AUTOSAR XML (schema 4-2-2)
package /ComponentTypes
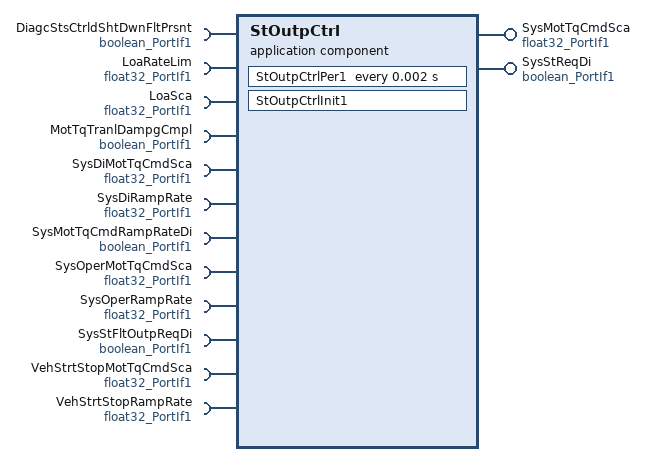
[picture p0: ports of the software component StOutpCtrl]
  application sw component type StOutpCtrl
    provide port SysMotTqCmdSca: nonqueued-sender-com-spec{data-element=Val, init-value=1}, provided-interface=float32_PortIf1
    provide port SysStReqDi: nonqueued-sender-com-spec{data-element=Logl, init-value=0}, provided-interface=boolean_PortIf1
    12 x require port:
      DiagcStsCtrldShtDwnFltPrsnt: nonqueued-receiver-com-spec{data-element=Logl, filter=data-filter-type=ALWAYS, init-value=0}, required-interface=boolean_PortIf1
      LoaRateLim: nonqueued-receiver-com-spec{data-element=Val, filter=data-filter-type=ALWAYS, init-value=1}, required-interface=float32_PortIf1
      LoaSca: nonqueued-receiver-com-spec{data-element=Val, filter=data-filter-type=ALWAYS, init-value=1}, required-interface=float32_PortIf1
      MotTqTranlDampgCmpl: nonqueued-receiver-com-spec{data-element=Logl, filter=data-filter-type=ALWAYS, init-value=0}, required-interface=boolean_PortIf1
      SysDiMotTqCmdSca: nonqueued-receiver-com-spec{data-element=Val, filter=data-filter-type=ALWAYS, init-value=1}, required-interface=float32_PortIf1
      SysDiRampRate: nonqueued-receiver-com-spec{data-element=Val, filter=data-filter-type=ALWAYS, init-value=1}, required-interface=float32_PortIf1
      SysMotTqCmdRampRateDi: nonqueued-receiver-com-spec{data-element=Logl, filter=data-filter-type=ALWAYS, init-value=0}, required-interface=boolean_PortIf1
      SysOperMotTqCmdSca: nonqueued-receiver-com-spec{data-element=Val, filter=data-filter-type=ALWAYS, init-value=1}, required-interface=float32_PortIf1
      SysOperRampRate: nonqueued-receiver-com-spec{data-element=Val, filter=data-filter-type=ALWAYS, init-value=1}, required-interface=float32_PortIf1
      SysStFltOutpReqDi: nonqueued-receiver-com-spec{data-element=Logl, filter=data-filter-type=ALWAYS, init-value=0}, required-interface=boolean_PortIf1
      VehStrtStopMotTqCmdSca: nonqueued-receiver-com-spec{data-element=Val, filter=data-filter-type=ALWAYS, init-value=1}, required-interface=float32_PortIf1
      VehStrtStopRampRate: nonqueued-receiver-com-spec{data-element=Val, filter=data-filter-type=ALWAYS, init-value=1}, required-interface=float32_PortIf1
    behavior StOutpCtrl_InternalBehavior
      ar-typed-per-instance-memorys:
        4 x data, all with sw-calibration-access=READ-ONLY:
          dStOutpCtrlRateLim: type=float32
          dStOutpCtrlTarSca: type=float32
          StOutpCtrlPrevCmdSca: type=float32
          StOutpCtrlPrevSrc: type=uint8
      init event StOutpCtrl_InitEvent: start-on-event=StOutpCtrlInit1
      timing event TMT_StOutpCtrlPer1: start-on-event=StOutpCtrlPer1, period=0.002
      port-api-options:
        enable-take-address=false, error-handling=NO-TRANSFORMER-ERROR-HANDLING, indirect-api=false, port=DiagcStsCtrldShtDwnFltPrsnt
        enable-take-address=false, error-handling=NO-TRANSFORMER-ERROR-HANDLING, indirect-api=false, port=LoaRateLim
        enable-take-address=false, error-handling=NO-TRANSFORMER-ERROR-HANDLING, indirect-api=false, port=LoaSca
        enable-take-address=false, error-handling=NO-TRANSFORMER-ERROR-HANDLING, indirect-api=false, port=MotTqTranlDampgCmpl
        enable-take-address=false, error-handling=NO-TRANSFORMER-ERROR-HANDLING, indirect-api=false, port=SysDiMotTqCmdSca
        enable-take-address=false, error-handling=NO-TRANSFORMER-ERROR-HANDLING, indirect-api=false, port=SysDiRampRate
        enable-take-address=false, error-handling=NO-TRANSFORMER-ERROR-HANDLING, indirect-api=false, port=SysMotTqCmdRampRateDi
        enable-take-address=false, error-handling=NO-TRANSFORMER-ERROR-HANDLING, indirect-api=false, port=SysMotTqCmdSca
        enable-take-address=false, error-handling=NO-TRANSFORMER-ERROR-HANDLING, indirect-api=false, port=SysOperMotTqCmdSca
        enable-take-address=false, error-handling=NO-TRANSFORMER-ERROR-HANDLING, indirect-api=false, port=SysOperRampRate
        enable-take-address=false, error-handling=NO-TRANSFORMER-ERROR-HANDLING, indirect-api=false, port=SysStFltOutpReqDi
        enable-take-address=false, error-handling=NO-TRANSFORMER-ERROR-HANDLING, indirect-api=false, port=SysStReqDi
        enable-take-address=false, error-handling=NO-TRANSFORMER-ERROR-HANDLING, indirect-api=false, port=VehStrtStopRampRate
      runnable StOutpCtrlInit1
      runnable StOutpCtrlPer1
        data-receive-point-by-arguments:
          12 x access:
            REC_DiagcStsCtrldShtDwnFltPrsnt_Logl_1: accessed-variable=DiagcStsCtrldShtDwnFltPrsnt.Logl
            REC_LoaRateLim_Val: accessed-variable=LoaRateLim.Val
            REC_LoaSca_Val: accessed-variable=LoaSca.Val
            REC_MotTqTranlDampgCmpl_Logl_1: accessed-variable=MotTqTranlDampgCmpl.Logl
            REC_SysDiMotTqCmdSca_Val_1: accessed-variable=SysDiMotTqCmdSca.Val
            REC_SysDiRampRate_Val_1: accessed-variable=SysDiRampRate.Val
            REC_SysMotTqCmdRampRateDi_Logl_1: accessed-variable=SysMotTqCmdRampRateDi.Logl
            REC_SysOperMotTqCmdSca_Val_1: accessed-variable=SysOperMotTqCmdSca.Val
            REC_SysOperRampRate_Val_1: accessed-variable=SysOperRampRate.Val
            REC_SysStFltOutpReqDi_Logl: accessed-variable=SysStFltOutpReqDi.Logl
            REC_VehStrtStopMotTqCmdSca_Val_1: accessed-variable=VehStrtStopMotTqCmdSca.Val
            REC_VehStrtStopRampRate_Val_1: accessed-variable=VehStrtStopRampRate.Val
        data-send-points:
          access SEND_SysMotTqCmdSca_Val_1: accessed-variable=SysMotTqCmdSca.Val
          access SEND_SysStReqDi_Logl_1: accessed-variable=SysStReqDi.Logl
  swc implementation StOutpCtrl_Implementation: behavior=StOutpCtrl_InternalBehavior
    code-descriptors:
      code Default: artifact-descriptors=autosar-engineering-object={short-label=Default, category=SWSRC}
